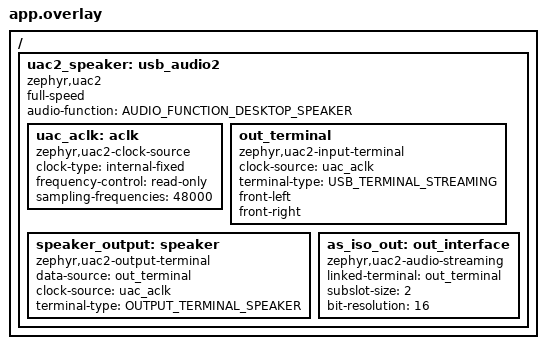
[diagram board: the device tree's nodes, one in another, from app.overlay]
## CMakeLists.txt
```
# Copyright (c) 2026 Troposound
# SPDX-License-Identifier: Apache-2.0

cmake_minimum_required(VERSION 3.20.0)
find_package(Zephyr REQUIRED HINTS $ENV{ZEPHYR_BASE})
project(usb_broadcast)

target_sources(app PRIVATE src/main.c src/usb.c src/broadcast.c)
```

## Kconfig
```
# Copyright (c) 2026 Troposound
# SPDX-License-Identifier: Apache-2.0

menu "USB broadcast sample"

config APP_USB_VID
	hex "USB vendor ID"
	default 0x1915

config APP_USB_PID
	hex "USB product ID"
	default 0x530D
	help
	  Distinct PID so hosts do not reuse cached descriptors from other
	  Troposound firmware.

config APP_USB_PRODUCT
	string "USB product string"
	default "Troposound R1 Broadcast" if BOARD_R1
	default "Troposound H1 Broadcast" if BOARD_H1
	default "Troposound Broadcast"

config BROADCAST_NAME
	string "Broadcast name"
	default "Troposound R1 USB" if BOARD_R1
	default "Troposound H1 USB" if BOARD_H1
	default "Troposound USB"
	help
	  Broadcast_Name AD shown by phones and broadcast assistants (4-32 bytes).

endmenu

source "Kconfig.zephyr"
```

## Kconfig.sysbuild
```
# Copyright (c) 2026 Troposound
# SPDX-License-Identifier: Apache-2.0

# Net core image, see sysbuild/ipc_radio/prj.conf
config NRF_DEFAULT_IPC_RADIO
	default y

config NETCORE_IPC_RADIO_BT_HCI_IPC
	default y

source "share/sysbuild/Kconfig"
```

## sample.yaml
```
# Copyright (c) 2026 Troposound
# SPDX-License-Identifier: Apache-2.0

sample:
  name: USB broadcast
  description: USB Audio Class 2 speaker broadcast as LE Audio (LC3, one BIS)
common:
  sysbuild: true
  build_only: true
  tags:
    - bluetooth
    - audio
    - usb
  integration_platforms:
    - h1/nrf5340/cpuapp
    - r1/nrf5340/cpuapp
  platform_allow:
    - h1/nrf5340/cpuapp
    - r1/nrf5340/cpuapp
tests:
  sample.troposound.usb_broadcast: {}
```

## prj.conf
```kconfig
# Copyright (c) 2026 Troposound
# SPDX-License-Identifier: Apache-2.0

CONFIG_LOG=y
CONFIG_MAIN_STACK_SIZE=4096

CONFIG_USB_DEVICE_STACK_NEXT=y
CONFIG_USBD_AUDIO2_CLASS=y
CONFIG_USBD_LOG_LEVEL_WRN=y
CONFIG_UDC_DRIVER_LOG_LEVEL_WRN=y
# USB serial number from FICR
CONFIG_HWINFO=y

CONFIG_BT=y
CONFIG_BT_AUDIO=y
CONFIG_BT_EXT_ADV=y
CONFIG_BT_ISO_BROADCASTER=y
CONFIG_BT_BAP_BROADCAST_SOURCE=y
CONFIG_BT_BAP_BROADCAST_SRC_STREAM_COUNT=2
CONFIG_BT_BAP_BROADCAST_SRC_SUBGROUP_COUNT=1
CONFIG_BT_PBP=y
CONFIG_BT_DEVICE_NAME="Troposound USB Broadcast"
CONFIG_UTF8=y

# Two BISes, left and right
CONFIG_BT_ISO_MAX_CHAN=2
CONFIG_BT_ISO_TX_BUF_COUNT=6
CONFIG_BT_ISO_TX_MTU=120

CONFIG_LIBLC3=y
CONFIG_FPU=y

CONFIG_TROPOSOUND_VOLUME=y
```

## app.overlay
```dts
/*
 * Copyright (c) 2026 Troposound
 *
 * SPDX-License-Identifier: Apache-2.0
 *
 * No IN stream for implicit feedback, so OUT uses an explicit feedback endpoint.
 */

#include <zephyr/dt-bindings/usb/audio.h>

/ {
	uac2_speaker: usb_audio2 {
		compatible = "zephyr,uac2";
		status = "okay";
		full-speed;
		audio-function = <AUDIO_FUNCTION_DESKTOP_SPEAKER>;

		uac_aclk: aclk {
			compatible = "zephyr,uac2-clock-source";
			clock-type = "internal-fixed";
			frequency-control = "read-only";
			sampling-frequencies = <48000>;
		};

		out_terminal: out_terminal {
			compatible = "zephyr,uac2-input-terminal";
			clock-source = <&uac_aclk>;
			terminal-type = <USB_TERMINAL_STREAMING>;
			front-left;
			front-right;
		};

		speaker_output: speaker {
			compatible = "zephyr,uac2-output-terminal";
			data-source = <&out_terminal>;
			clock-source = <&uac_aclk>;
			terminal-type = <OUTPUT_TERMINAL_SPEAKER>;
		};

		as_iso_out: out_interface {
			compatible = "zephyr,uac2-audio-streaming";
			linked-terminal = <&out_terminal>;
			subslot-size = <2>;
			bit-resolution = <16>;
		};
	};
};
```

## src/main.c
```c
/*
 * Copyright (c) 2026 Troposound
 *
 * SPDX-License-Identifier: Apache-2.0
 */

#include <nrfx_clock.h>
#include <troposound/volume.h>
#include <zephyr/drivers/gpio.h>
#include <zephyr/kernel.h>
#include <zephyr/logging/log.h>

#include "usb_broadcast.h"

LOG_MODULE_REGISTER(usb_broadcast, LOG_LEVEL_INF);

#define USER_NODE DT_PATH(zephyr_user)

static const struct gpio_dt_spec on_led = GPIO_DT_SPEC_GET(DT_ALIAS(led1), gpios);

#if DT_NODE_HAS_PROP(USER_NODE, amp_enable_gpios)
/* Nothing plays locally */
static const struct gpio_dt_spec amp_en = GPIO_DT_SPEC_GET(USER_NODE, amp_enable_gpios);
#endif

int main(void)
{
	int err;

#if DT_NODE_HAS_PROP(USER_NODE, amp_enable_gpios)
	(void)gpio_pin_configure_dt(&amp_en, GPIO_OUTPUT_INACTIVE);
#endif

	/* LC3 encoding needs 128 MHz */
	err = nrfx_clock_divider_set(NRF_CLOCK_DOMAIN_HFCLK, NRF_CLOCK_HFCLK_DIV_1);
	if (err) {
		LOG_WRN("Could not set 128 MHz (%d)", err);
	}

	LOG_INF("USB broadcast on %s", CONFIG_BOARD_TARGET);

	err = broadcast_start();
	if (err) {
		LOG_ERR("Broadcast start failed (%d)", err);
		return err;
	}

	/* Encoder only; the R1 knob reports its position */
	err = volume_start_cb(usb_volume_set, 0);
	if (err) {
		return err;
	}

	err = usb_start();
	if (err) {
		return err;
	}

	(void)gpio_pin_configure_dt(&on_led, GPIO_OUTPUT_ACTIVE);

	while (true) {
		k_sleep(K_SECONDS(10));
		usb_stats_log();
	}
}
```

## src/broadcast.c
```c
/*
 * Copyright (c) 2026 Troposound
 *
 * SPDX-License-Identifier: Apache-2.0
 */

/* Each sent left SDU releases the next frame pair, so encoding runs on the BIG clock */

#include <lc3.h>
#include <zephyr/bluetooth/audio/audio.h>
#include <zephyr/bluetooth/audio/bap.h>
#include <zephyr/bluetooth/audio/bap_lc3_preset.h>
#include <zephyr/bluetooth/audio/pbp.h>
#include <zephyr/bluetooth/bluetooth.h>
#include <zephyr/bluetooth/crypto.h>
#include <zephyr/bluetooth/iso.h>
#include <zephyr/bluetooth/uuid.h>
#include <zephyr/kernel.h>
#include <zephyr/logging/log.h>
#include <zephyr/net_buf.h>
#include <zephyr/sys/atomic.h>

#include "usb_broadcast.h"

LOG_MODULE_REGISTER(broadcast, LOG_LEVEL_INF);

BUILD_ASSERT(IN_RANGE(sizeof(CONFIG_BROADCAST_NAME) - 1, BT_AUDIO_BROADCAST_NAME_LEN_MIN,
		      BT_AUDIO_BROADCAST_NAME_LEN_MAX),
	     "Invalid broadcast name length");

#define CHANNELS     2
#define TX_IN_FLIGHT 2

BUILD_ASSERT(CONFIG_BT_ISO_TX_BUF_COUNT >= CHANNELS * (TX_IN_FLIGHT + 1),
	     "Need a spare ISO TX buffer per channel");

static struct bt_bap_lc3_preset preset = BT_BAP_LC3_BROADCAST_PRESET_48_4_1(
	BT_AUDIO_LOCATION_FRONT_LEFT | BT_AUDIO_LOCATION_FRONT_RIGHT, BT_AUDIO_CONTEXT_TYPE_MEDIA);

static uint8_t bis_left[] = {BT_AUDIO_CODEC_DATA(BT_AUDIO_CODEC_CFG_CHAN_ALLOC,
						 BT_BYTES_LIST_LE32(BT_AUDIO_LOCATION_FRONT_LEFT))};
static uint8_t bis_right[] = {BT_AUDIO_CODEC_DATA(
	BT_AUDIO_CODEC_CFG_CHAN_ALLOC, BT_BYTES_LIST_LE32(BT_AUDIO_LOCATION_FRONT_RIGHT))};

NET_BUF_POOL_FIXED_DEFINE(tx_pool, CONFIG_BT_ISO_TX_BUF_COUNT,
			  BT_ISO_SDU_BUF_SIZE(CONFIG_BT_ISO_TX_MTU),
			  CONFIG_BT_CONN_TX_USER_DATA_SIZE, NULL);

static struct bt_bap_stream streams[CHANNELS];
static struct bt_bap_broadcast_source *source;
static atomic_t started;
static atomic_t streaming;
static atomic_t in_flight;
static uint16_t seq_num;

static lc3_encoder_mem_48k_t lc3_mem[CHANNELS];
static lc3_encoder_t lc3_enc[CHANNELS];

static K_SEM_DEFINE(sem_tx, 0, 1);
static K_SEM_DEFINE(sem_started, 0, 1);

static int frame_send(void)
{
	const int octets = preset.qos.sdu;
	uint32_t pcm[FRAME_SAMPLES];
	struct net_buf *bufs[CHANNELS] = {0};
	int ret = 0;

	for (size_t ch = 0; ch < CHANNELS; ch++) {
		bufs[ch] = net_buf_alloc(&tx_pool, K_NO_WAIT);
		if (bufs[ch] == NULL) {
			ret = -ENOMEM;
		}
	}

	usb_frame_get(pcm);

	for (size_t ch = 0; ch < CHANNELS && ret == 0; ch++) {
		net_buf_reserve(bufs[ch], BT_ISO_CHAN_SEND_RESERVE);
		if (lc3_encode(lc3_enc[ch], LC3_PCM_FORMAT_S16, (const int16_t *)pcm + ch, 2,
			       octets, net_buf_add(bufs[ch], octets)) != 0) {
			ret = -EIO;
		}
	}

	if (ret) {
		for (size_t ch = 0; ch < CHANNELS; ch++) {
			if (bufs[ch] != NULL) {
				net_buf_unref(bufs[ch]);
			}
		}
		return ret;
	}

	atomic_inc(&in_flight);

	for (size_t ch = 0; ch < CHANNELS; ch++) {
		int err = bt_bap_stream_send(&streams[ch], bufs[ch], seq_num);

		if (err) {
			net_buf_unref(bufs[ch]);
			if (ch == 0) {
				atomic_dec(&in_flight);
			}
			ret = err;
		}
	}

	seq_num++;
	return ret;
}

static void encoder_thread(void *p1, void *p2, void *p3)
{
	uint32_t errors = 0;

	while (true) {
		/* Timeout retries after a failed send */
		(void)k_sem_take(&sem_tx, K_MSEC(FRAME_MS));

		while (atomic_get(&streaming) && atomic_get(&in_flight) < TX_IN_FLIGHT) {
			int err = frame_send();

			if (err) {
				if ((errors++ % 100U) == 0U) {
					LOG_WRN("SDU send failed (%d), %u so far", err, errors);
				}
				break;
			}
		}
	}
}

/* Below the Bluetooth threads */
K_THREAD_DEFINE(encoder_tid, 6144, encoder_thread, NULL, NULL, NULL, 10, 0, 0);

static void stream_started_cb(struct bt_bap_stream *s)
{
	LOG_INF("BIS %s started", s == &streams[0] ? "left" : "right");

	if (atomic_inc(&started) + 1 < CHANNELS) {
		return;
	}

	seq_num = 0;
	atomic_set(&in_flight, 0);
	atomic_set(&streaming, 1);
	k_sem_give(&sem_tx);
	k_sem_give(&sem_started);
}

static void stream_stopped_cb(struct bt_bap_stream *s, uint8_t reason)
{
	atomic_dec(&started);
	atomic_set(&streaming, 0);
	LOG_WRN("BIS %s stopped (0x%02x)", s == &streams[0] ? "left" : "right", reason);
}

static void stream_sent_cb(struct bt_bap_stream *s)
{
	if (s == &streams[0]) {
		atomic_dec(&in_flight);
		k_sem_give(&sem_tx);
	}
}

static struct bt_bap_stream_ops stream_ops = {
	.started = stream_started_cb,
	.stopped = stream_stopped_cb,
	.sent = stream_sent_cb,
};

static int create_source(void)
{
	struct bt_bap_broadcast_source_stream_param stream_params[CHANNELS] = {
		{.stream = &streams[0], .data = bis_left, .data_len = sizeof(bis_left)},
		{.stream = &streams[1], .data = bis_right, .data_len = sizeof(bis_right)},
	};
	struct bt_bap_broadcast_source_subgroup_param subgroup_param = {
		.params_count = CHANNELS,
		.params = stream_params,
		.codec_cfg = &preset.codec_cfg,
	};
	struct bt_bap_broadcast_source_param param = {
		.params_count = 1,
		.params = &subgroup_param,
		.qos = &preset.qos,
		.encryption = false,
		.packing = BT_ISO_PACKING_SEQUENTIAL,
	};

	for (size_t ch = 0; ch < CHANNELS; ch++) {
		bt_bap_stream_cb_register(&streams[ch], &stream_ops);
	}

	return bt_bap_broadcast_source_create(&param, &source);
}

static int start_advertising(void)
{
	NET_BUF_SIMPLE_DEFINE(id_buf, BT_UUID_SIZE_16 + BT_AUDIO_BROADCAST_ID_SIZE);
	NET_BUF_SIMPLE_DEFINE(pba_buf, BT_UUID_SIZE_16 + 2 + 16);
	NET_BUF_SIMPLE_DEFINE(base_buf, 128);
	struct bt_le_ext_adv *adv;
	struct bt_data ext_ad[3];
	struct bt_data per_ad;
	uint32_t broadcast_id;
	int err;

	err = bt_le_ext_adv_create(BT_BAP_ADV_PARAM_BROADCAST_FAST, NULL, &adv);
	if (err) {
		LOG_ERR("ext_adv_create failed (%d)", err);
		return err;
	}

	err = bt_le_per_adv_set_param(adv, BT_BAP_PER_ADV_PARAM_BROADCAST_FAST);
	if (err) {
		LOG_ERR("per_adv_set_param failed (%d)", err);
		return err;
	}

	err = bt_rand(&broadcast_id, BT_AUDIO_BROADCAST_ID_SIZE);
	if (err) {
		return err;
	}
	broadcast_id &= BIT_MASK(24);

	net_buf_simple_add_le16(&id_buf, BT_UUID_BROADCAST_AUDIO_VAL);
	net_buf_simple_add_le24(&id_buf, broadcast_id);
	ext_ad[0] = (struct bt_data)BT_DATA(BT_DATA_SVC_DATA16, id_buf.data, id_buf.len);

	err = bt_pbp_get_announcement(NULL, 0, BT_PBP_ANNOUNCEMENT_FEATURE_HIGH_QUALITY, &pba_buf);
	if (err) {
		LOG_ERR("PBP announcement failed (%d)", err);
		return err;
	}
	ext_ad[1] = (struct bt_data)BT_DATA(BT_DATA_SVC_DATA16, pba_buf.data, pba_buf.len);

	ext_ad[2] = (struct bt_data)BT_DATA(BT_DATA_BROADCAST_NAME, CONFIG_BROADCAST_NAME,
					    sizeof(CONFIG_BROADCAST_NAME) - 1);

	err = bt_le_ext_adv_set_data(adv, ext_ad, ARRAY_SIZE(ext_ad), NULL, 0);
	if (err) {
		LOG_ERR("ext_adv_set_data failed (%d)", err);
		return err;
	}

	err = bt_bap_broadcast_source_get_base(source, &base_buf);
	if (err) {
		LOG_ERR("get_base failed (%d)", err);
		return err;
	}

	per_ad = (struct bt_data)BT_DATA(BT_DATA_SVC_DATA16, base_buf.data, base_buf.len);
	err = bt_le_per_adv_set_data(adv, &per_ad, 1);
	if (err) {
		LOG_ERR("per_adv_set_data failed (%d)", err);
		return err;
	}

	err = bt_le_ext_adv_start(adv, BT_LE_EXT_ADV_START_DEFAULT);
	if (err) {
		LOG_ERR("ext_adv_start failed (%d)", err);
		return err;
	}

	err = bt_le_per_adv_start(adv);
	if (err) {
		LOG_ERR("per_adv_start failed (%d)", err);
		return err;
	}

	err = bt_bap_broadcast_source_start(source, adv);
	if (err) {
		LOG_ERR("broadcast_source_start failed (%d)", err);
		return err;
	}

	LOG_INF("Advertising \"%s\", broadcast ID 0x%06x, LC3 48 kHz stereo, %u octets",
		CONFIG_BROADCAST_NAME, broadcast_id, preset.qos.sdu);
	return 0;
}

int broadcast_start(void)
{
	int err;

	for (size_t ch = 0; ch < CHANNELS; ch++) {
		lc3_enc[ch] = lc3_setup_encoder(FRAME_MS * USEC_PER_MSEC, PCM_RATE_HZ, PCM_RATE_HZ,
						&lc3_mem[ch]);
		if (lc3_enc[ch] == NULL) {
			LOG_ERR("LC3 encoder setup failed");
			return -EINVAL;
		}
	}

	err = bt_enable(NULL);
	if (err) {
		LOG_ERR("bt_enable failed (%d)", err);
		return err;
	}

	err = create_source();
	if (err) {
		LOG_ERR("broadcast_source_create failed (%d)", err);
		return err;
	}

	err = start_advertising();
	if (err) {
		return err;
	}

	return k_sem_take(&sem_started, K_SECONDS(5));
}
```

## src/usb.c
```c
/*
 * Copyright (c) 2026 Troposound
 *
 * SPDX-License-Identifier: Apache-2.0
 */

/*
 * The BIG clocks the audio out. Explicit feedback holds the ring level right
 * after each frame is taken (the sawtooth low point) at FB_TARGET.
 */

#include <math.h>
#include <string.h>

#include <zephyr/device.h>
#include <zephyr/drivers/usb/usb_buf.h>
#include <zephyr/kernel.h>
#include <zephyr/logging/log.h>
#include <zephyr/sys/atomic.h>
#include <zephyr/sys/util.h>
#include <zephyr/usb/class/usbd_uac2.h>
#include <zephyr/usb/usbd.h>
#include <zephyr/usb/usbd_msg.h>

#include "usb_broadcast.h"

LOG_MODULE_REGISTER(usb, LOG_LEVEL_INF);

#define OUT_TERMINAL_ID UAC2_ENTITY_ID(DT_NODELABEL(out_terminal))

#define FRAMES_PER_MS      (PCM_RATE_HZ / 1000)
#define STEREO_FRAME_BYTES (2 * sizeof(int16_t))
/* Async: up to one extra frame per USB frame */
#define RECV_MAX_BYTES     ((FRAMES_PER_MS + 1) * STEREO_FRAME_BYTES)

/* Must be a power of two, counters run free */
#define RING_FRAMES 2048U

/* Q10.14 samples per USB frame. One LSB is 1.27 ppm. */
#define FB_FRAC_BITS  14
#define FB_NOMINAL    (FRAMES_PER_MS << FB_FRAC_BITS)
#define FB_TARGET     (5 * FRAMES_PER_MS)
#define FB_WARMUP     20 /* frames after priming before the level counts */
#define FB_EWMA_SHIFT 8  /* 256 ms at one update per SOF */
#define FB_GAIN       4  /* LSB per sample of error: about 4 s to settle */
#define FB_MAX_DEV    2048

#define GAIN_SHIFT 14
#define GAIN_UNITY BIT(GAIN_SHIFT)

BUILD_ASSERT(FRAME_SAMPLES + FB_TARGET < RING_FRAMES / 2, "Ring too small");

/* Left in the low half-word, as on the wire */
static uint32_t ring[RING_FRAMES];
static atomic_t ring_head;
static atomic_t ring_tail;

static atomic_t stream_on;
static atomic_t gain_q14 = ATOMIC_INIT(GAIN_UNITY);
static atomic_t trough = ATOMIC_INIT(-1); /* -1 until primed and settled */
static atomic_t fb_dev;
static atomic_t underruns;
static atomic_t overruns;

static bool primed;     /* encoder only */
static int settle;      /* encoder only */
static int32_t err_acc; /* USB only: filtered error << FB_EWMA_SHIFT */

K_MEM_SLAB_DEFINE_STATIC(recv_slab, ROUND_UP(RECV_MAX_BYTES, UDC_BUF_GRANULARITY), 4,
			 UDC_BUF_ALIGN);

static const struct device *const uac2_dev = DEVICE_DT_GET(DT_NODELABEL(uac2_speaker));

USBD_DEVICE_DEFINE(usbd_ctx, DEVICE_DT_GET(DT_NODELABEL(zephyr_udc0)), CONFIG_APP_USB_VID,
		   CONFIG_APP_USB_PID);
USBD_DESC_LANG_DEFINE(desc_lang);
USBD_DESC_MANUFACTURER_DEFINE(desc_mfr, "Troposound");
USBD_DESC_PRODUCT_DEFINE(desc_product, CONFIG_APP_USB_PRODUCT);
USBD_DESC_SERIAL_NUMBER_DEFINE(desc_serial);
USBD_CONFIGURATION_DEFINE(fs_config, 0, 100, NULL);

void usb_volume_set(int half_db)
{
	atomic_set(&gain_q14, lroundf(GAIN_UNITY * powf(10.0f, half_db / 40.0f)));
}

void usb_frame_get(uint32_t *pcm)
{
	uint32_t head = (uint32_t)atomic_get(&ring_head);
	uint32_t tail = (uint32_t)atomic_get(&ring_tail);
	uint32_t avail = head - tail;

	if (!atomic_get(&stream_on)) {
		/* Consumer-side flush */
		atomic_set(&ring_tail, head);
		primed = false;
	} else if (!primed && avail >= FRAME_SAMPLES + FB_TARGET) {
		primed = true;
		settle = FB_WARMUP;
	} else if (primed && avail < FRAME_SAMPLES) {
		atomic_inc(&underruns);
		primed = false;
	}

	if (!primed) {
		atomic_set(&trough, -1);
		memset(pcm, 0, FRAME_SAMPLES * sizeof(uint32_t));
		return;
	}

	for (uint32_t i = 0; i < FRAME_SAMPLES; i++) {
		pcm[i] = ring[(tail + i) & (RING_FRAMES - 1)];
	}
	atomic_set(&ring_tail, tail + FRAME_SAMPLES);

	if (settle > 0) {
		settle--;
	}
	atomic_set(&trough, settle > 0 ? -1 : (atomic_val_t)(avail - FRAME_SAMPLES));
}

static void sof_cb(const struct device *dev, void *user_data)
{
	ARG_UNUSED(dev);
	ARG_UNUSED(user_data);
}

static void terminal_update_cb(const struct device *dev, uint8_t terminal, bool enabled,
			       bool microframes, void *user_data)
{
	ARG_UNUSED(dev);
	ARG_UNUSED(microframes);
	ARG_UNUSED(user_data);

	if (terminal == OUT_TERMINAL_ID) {
		atomic_set(&stream_on, enabled);
		LOG_INF("Host stream %s", enabled ? "started" : "stopped");
	}
}

static void *get_recv_buf(const struct device *dev, uint8_t terminal, uint16_t size,
			  void *user_data)
{
	void *buf;

	ARG_UNUSED(dev);
	ARG_UNUSED(user_data);

	if (terminal != OUT_TERMINAL_ID || size > RECV_MAX_BYTES) {
		return NULL;
	}

	if (k_mem_slab_alloc(&recv_slab, &buf, K_NO_WAIT) != 0) {
		return NULL;
	}

	return buf;
}

static uint16_t scale(int16_t sample, int32_t gain)
{
	int32_t v = ((int32_t)sample * gain) >> GAIN_SHIFT;

	return (uint16_t)CLAMP(v, INT16_MIN, INT16_MAX);
}

static void data_recv_cb(const struct device *dev, uint8_t terminal, void *buf, uint16_t size,
			 void *user_data)
{
	const int16_t *pcm = buf;
	const int32_t gain = (int32_t)atomic_get(&gain_q14);
	uint32_t head = (uint32_t)atomic_get(&ring_head);
	uint32_t space = RING_FRAMES - (head - (uint32_t)atomic_get(&ring_tail));
	uint32_t n = size / STEREO_FRAME_BYTES;

	ARG_UNUSED(dev);
	ARG_UNUSED(terminal);
	ARG_UNUSED(user_data);

	if (atomic_get(&stream_on)) {
		if (n > space) {
			atomic_inc(&overruns);
			n = space;
		}

		for (uint32_t i = 0; i < n; i++) {
			ring[(head + i) & (RING_FRAMES - 1)] =
				scale(pcm[2 * i], gain) |
				((uint32_t)scale(pcm[2 * i + 1], gain) << 16);
		}
		atomic_set(&ring_head, head + n);
	}

	k_mem_slab_free(&recv_slab, buf);
}

static uint32_t feedback_cb(const struct device *dev, uint8_t terminal, void *user_data)
{
	int32_t fill = (int32_t)atomic_get(&trough);
	int32_t dev_lsb;

	ARG_UNUSED(dev);
	ARG_UNUSED(terminal);
	ARG_UNUSED(user_data);

	if (fill < 0) {
		err_acc = 0;
		atomic_set(&fb_dev, 0);
		return FB_NOMINAL;
	}

	err_acc += (fill - FB_TARGET) - (err_acc >> FB_EWMA_SHIFT);

	/* Above target the host is ahead of the BIG */
	dev_lsb = CLAMP(-(err_acc >> FB_EWMA_SHIFT) * FB_GAIN, -FB_MAX_DEV, FB_MAX_DEV);
	atomic_set(&fb_dev, dev_lsb);

	return FB_NOMINAL + dev_lsb;
}

static const struct uac2_ops uac2_ops = {
	.sof_cb = sof_cb,
	.terminal_update_cb = terminal_update_cb,
	.get_recv_buf = get_recv_buf,
	.data_recv_cb = data_recv_cb,
	.feedback_cb = feedback_cb,
};

void usb_stats_log(void)
{
	if (!atomic_get(&stream_on)) {
		return;
	}

	LOG_INF("fill=%d feedback=%+d ppm underruns=%u overruns=%u", (int)atomic_get(&trough),
		(int)(atomic_get(&fb_dev) * 1000000LL / FB_NOMINAL),
		(uint32_t)atomic_set(&underruns, 0), (uint32_t)atomic_set(&overruns, 0));
}

static void usbd_msg_cb(struct usbd_context *const ctx, const struct usbd_msg *const msg)
{
	LOG_INF("USB: %s", usbd_msg_type_string(msg->type));

	if (!usbd_can_detect_vbus(ctx)) {
		return;
	}

	if (msg->type == USBD_MSG_VBUS_READY) {
		if (usbd_enable(ctx) != 0) {
			LOG_ERR("usbd_enable failed");
		}
	} else if (msg->type == USBD_MSG_VBUS_REMOVED) {
		if (usbd_disable(ctx) != 0) {
			LOG_ERR("usbd_disable failed");
		}
	}
}

int usb_start(void)
{
	int ret;

	usbd_uac2_set_ops(uac2_dev, &uac2_ops, NULL);

	ret = usbd_add_descriptor(&usbd_ctx, &desc_lang);
	ret = ret ? ret : usbd_add_descriptor(&usbd_ctx, &desc_mfr);
	ret = ret ? ret : usbd_add_descriptor(&usbd_ctx, &desc_product);
	ret = ret ? ret : usbd_add_descriptor(&usbd_ctx, &desc_serial);
	ret = ret ? ret : usbd_add_configuration(&usbd_ctx, USBD_SPEED_FS, &fs_config);
	ret = ret ? ret : usbd_register_all_classes(&usbd_ctx, USBD_SPEED_FS, 1, NULL);
	if (ret) {
		LOG_ERR("USB descriptor/class setup failed: %d", ret);
		return ret;
	}

	/* IAD device class */
	usbd_device_set_code_triple(&usbd_ctx, USBD_SPEED_FS, USB_BCC_MISCELLANEOUS, 0x02, 0x01);

	ret = usbd_msg_register_cb(&usbd_ctx, usbd_msg_cb);
	ret = ret ? ret : usbd_init(&usbd_ctx);
	if (ret) {
		LOG_ERR("USB init failed: %d", ret);
		return ret;
	}

	if (!usbd_can_detect_vbus(&usbd_ctx)) {
		ret = usbd_enable(&usbd_ctx);
	}

	return ret;
}
```

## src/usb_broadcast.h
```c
/*
 * Copyright (c) 2026 Troposound
 *
 * SPDX-License-Identifier: Apache-2.0
 */

#ifndef USB_BROADCAST_H_
#define USB_BROADCAST_H_

#include <stdint.h>

#define PCM_RATE_HZ   48000
#define FRAME_MS      10
#define FRAME_SAMPLES (PCM_RATE_HZ / 1000 * FRAME_MS)

int usb_start(void);
void usb_volume_set(int half_db);
void usb_stats_log(void);

/* One frame, left in the low half-word; silence when the host is idle */
void usb_frame_get(uint32_t *pcm);

/* Returns once both BISes are up */
int broadcast_start(void);

#endif /* USB_BROADCAST_H_ */
```
